VERSION "f34"

NS_ :

BS_:

BU_: C70 VC BMS CHG DASH PBX MCAN OA

BO_ 1286 DS_RC_Outputs: 8 DS
 SG_ DS_Steer : 0|16@1+ (1,0) [0|0] "" Vector__XXX
 SG_ DS_Throttle : 16|16@1+ (1,0) [0|0] "" Vector__XXX

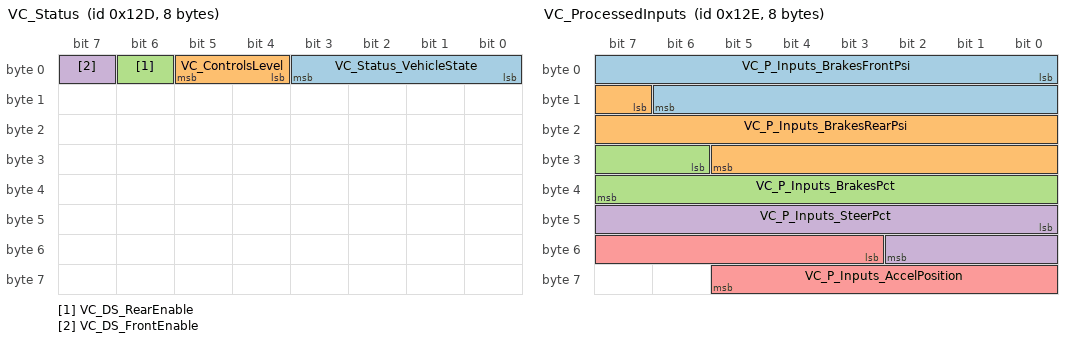
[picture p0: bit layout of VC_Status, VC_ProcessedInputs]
BO_ 301 VC_Status: 8 VC
 SG_ VC_Status_VehicleState : 0|4@1+ (1,0) [0|15] ""  Vector__XXX
 SG_ VC_ControlsLevel : 4|2@1+ (1,0) [0|0] "" Vector__XXX
 SG_ VC_DS_RearEnable : 6|1@1+ (1,0) [0|0] "" Vector__XXX
 SG_ VC_DS_FrontEnable : 7|1@1+ (1,0) [0|0] "" Vector__XXX

BO_ 302 VC_ProcessedInputs: 8 VC
 SG_ VC_P_Inputs_BrakesFrontPsi : 0|15@1+ (0.1,0) [0|3000] "psi" Vector__XXX
 SG_ VC_P_Inputs_BrakesRearPsi : 15|15@1+ (0.1,0) [0|3000] "psi" Vector__XXX
 SG_ VC_P_Inputs_BrakesPct : 30|10@1+ (0.1,0) [0|100] "%" Vector__XXX
 SG_ VC_P_Inputs_SteerPct : 40|11@1- (0.1,0) [-100|100] "%" Vector__XXX
 SG_ VC_P_Inputs_AccelPosition : 51|11@1- (0.1,0) [-100|100] "%" Vector__XXX

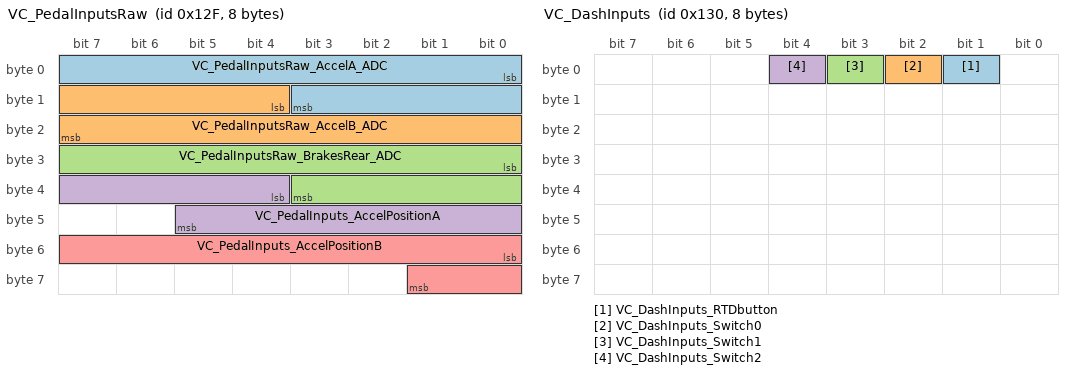
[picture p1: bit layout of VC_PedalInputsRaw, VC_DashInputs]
BO_ 303 VC_PedalInputsRaw: 8 VC
 SG_ VC_PedalInputsRaw_AccelA_ADC : 0|12@1+ (1,0) [0|4095] "" Vector__XXX
 SG_ VC_PedalInputsRaw_AccelB_ADC : 12|12@1+ (1,0) [0|4095] "" Vector__XXX
 SG_ VC_PedalInputsRaw_BrakesRear_ADC : 24|12@1+ (1,0) [0|4095] "" Vector__XXX
 SG_ VC_PedalInputs_AccelPositionA : 36|10@1+ (0.1,0) [0|100] "%" Vector__XXX
 SG_ VC_PedalInputs_AccelPositionB : 48|10@1+ (0.1,0) [0|100] "%" Vector__XXX

BO_ 304 VC_DashInputs: 8 VC
 SG_ VC_DashInputs_RTDbutton : 1|1@1+ (1,0) [0|1] "" Vector__XXX
 SG_ VC_DashInputs_Switch0 : 2|1@1+ (1,0) [0|1] "" Vector__XXX
 SG_ VC_DashInputs_Switch1 : 3|1@1+ (1,0) [0|1] "" Vector__XXX
 SG_ VC_DashInputs_Switch2 : 4|1@1+ (1,0) [0|1] "" Vector__XXX

BO_ 311 VC_FaultVector: 8 VC
 SG_ VC_PBX_SHUTDOWN_CONTROL : 0|1@1+ (1,0) [0|1] ""  Vector__XXX
 SG_ VC_ShutdownStatus_BMS_fault : 1|1@1+ (1,0) [0|1] "" Vector__XXX
 SG_ VC_FaultVector_ACCEL_A_IRRA : 2|1@1+ (1,0) [0|1] "" Vector__XXX
 SG_ VC_FaultVector_ACCEL_B_IRRA : 3|1@1+ (1,0) [0|1] "" Vector__XXX
 SG_ VC_FaultVector_APPS_DISAG : 4|1@1+ (1,0) [0|1] "" Vector__XXX
 SG_ VC_FaultVector_APPS_DOUBLE_PEDAL : 5|1@1+ (1,0) [0|1] "" Vector__XXX
 SG_ VC_FaultVector_FSSDB_LOST : 6|1@1+ (1,0) [0|1] "" Vector__XXX
 SG_ VC_FaultVector_FBPS_IRRA : 7|1@1+ (1,0) [0|1] "" Vector__XXX
 SG_ VC_FaultVector_RBPS_IRRA : 8|1@1+ (1,0) [0|1] "" Vector__XXX
 SG_ VC_FaultVector_STEER_IRRA : 9|1@1+ (1,0) [0|1] ""  Vector__XXX
 SG_ VC_FaultVector_RSSDB_LOST : 10|1@1+ (1,0) [0|1] ""  Vector__XXX
 SG_ VC_FaultVector_RR_ERROR : 11|1@1+ (1,0) [0|1] ""  Vector__XXX
 SG_ VC_FaultVector_RL_ERROR : 12|1@1+ (1,0) [0|1] ""  Vector__XXX
 SG_ VC_FaultVector_FR_ERROR : 13|1@1+ (1,0) [0|1] ""  Vector__XXX
 SG_ VC_FaultVector_FL_ERROR : 14|1@1+ (1,0) [0|1] ""  Vector__XXX
 SG_ VC_FaultVector_PC_TIMEOUT : 15|1@1+ (1,0) [0|1] "" Vector__XXX
 SG_ VC_FaultVector_SOFT_DP : 16|1@1+ (1,0) [0|1] "" Vector__XXX
 SG_ VC_FaultVector_VN_NO_LOCK : 17|1@1+ (1,0) [0|1] "" Vector__XXX
 SG_ VC_FaultVector_VN_IRR : 18|1@1+ (1,0) [0|1] "" Vector__XXX
 SG_ VC_FaultVector_RUNAWAY : 19|1@1+ (1,0) [0|1] "" Vector__XXX
 SG_ VC_FaultVector_CURRENT_IRR : 20|1@1+ (1,0) [0|1] "" Vector__XXX
 SG_ VC_FaultVector_VN_LOST : 21|1@1+ (1,0) [0|1] "" Vector__XXX

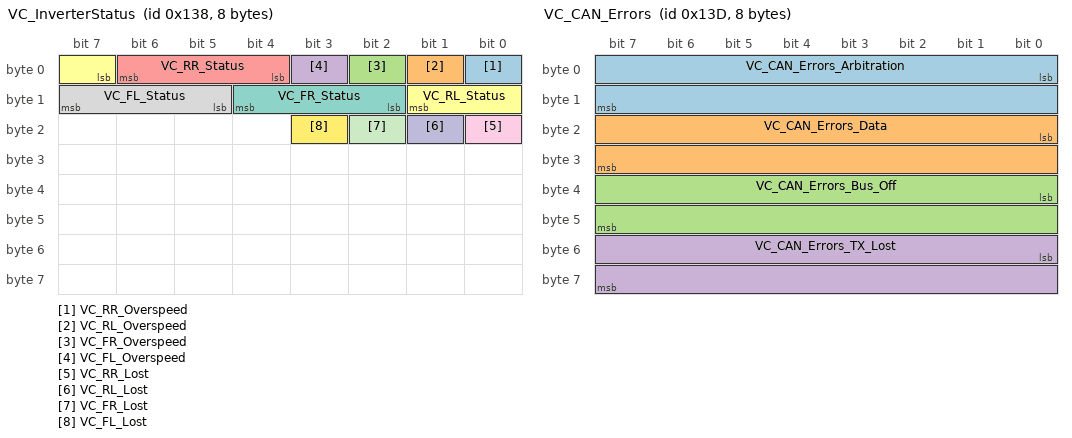
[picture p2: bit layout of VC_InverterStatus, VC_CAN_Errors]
BO_ 312 VC_InverterStatus: 8 VC
 SG_ VC_RR_Overspeed : 0|1@1+ (1,0) [0|1] "" Vector__XXX
 SG_ VC_RL_Overspeed : 1|1@1+ (1,0) [0|1] "" Vector__XXX
 SG_ VC_FR_Overspeed : 2|1@1+ (1,0) [0|1] "" Vector__XXX
 SG_ VC_FL_Overspeed : 3|1@1+ (1,0) [0|1] "" Vector__XXX
 SG_ VC_RR_Status : 4|3@1+ (1,0) [0|7] "" Vector__XXX
 SG_ VC_RL_Status : 7|3@1+ (1,0) [0|7] "" Vector__XXX
 SG_ VC_FR_Status : 10|3@1+ (1,0) [0|7] "" Vector__XXX
 SG_ VC_FL_Status : 13|3@1+ (1,0) [0|7] "" Vector__XXX
 SG_ VC_RR_Lost : 16|1@1+ (1,0) [0|1] "" Vector__XXX
 SG_ VC_RL_Lost : 17|1@1+ (1,0) [0|1] "" Vector__XXX
 SG_ VC_FR_Lost : 18|1@1+ (1,0) [0|1] "" Vector__XXX
 SG_ VC_FL_Lost : 19|1@1+ (1,0) [0|1] "" Vector__XXX

BO_ 315 VC_HardFaultIndicator: 8 VC
 SG_ VC_HardFaultIndicator : 0|4@1+ (1,0) [0|15] ""  DASH

BO_ 316 VC_RTDSRequest: 8 VC
 SG_ VC_RequestRTDS : 0|1@1+ (1,0) [0|1] "" Vector__XXX

BO_ 317 VC_CAN_Errors: 8 VC
 SG_ VC_CAN_Errors_Arbitration : 0|16@1+ (1,0) [0|0] "" Vector__XXX
 SG_ VC_CAN_Errors_Data : 16|16@1+ (1,0) [0|0] "" Vector__XXX
 SG_ VC_CAN_Errors_Bus_Off : 32|16@1+ (1,0) [0|0] "" Vector__XXX
 SG_ VC_CAN_Errors_TX_Lost : 48|16@1+ (1,0) [0|0] "" Vector__XXX

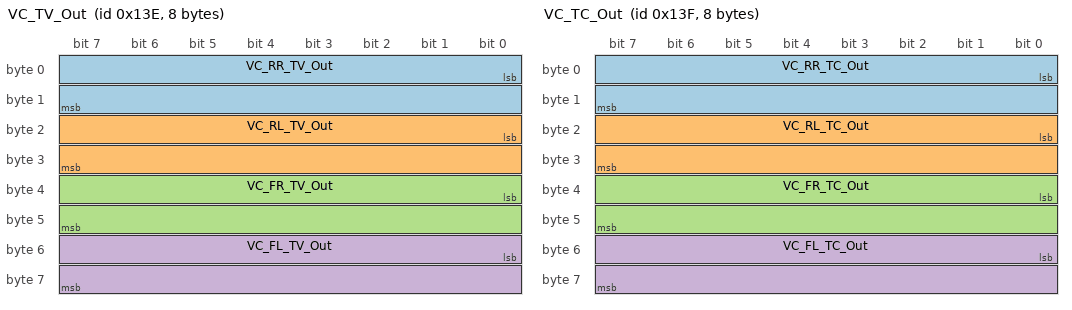
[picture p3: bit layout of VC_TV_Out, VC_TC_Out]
BO_ 318 VC_TV_Out: 8 VC
 SG_ VC_RR_TV_Out: 0|16@1+ (0.1,0) [0|0] "% Mn" Vector__XXX
 SG_ VC_RL_TV_Out: 16|16@1+ (0.1,0) [0|0] "% Mn" Vector__XXX
 SG_ VC_FR_TV_Out: 32|16@1+ (0.1,0) [0|0] "% Mn" Vector__XXX
 SG_ VC_FL_TV_Out: 48|16@1+ (0.1,0) [0|0] "% Mn" Vector__XXX

BO_ 319 VC_TC_Out: 8 VC
 SG_ VC_RR_TC_Out: 0|16@1+ (0.1,0) [0|0] "% Mn" Vector__XXX
 SG_ VC_RL_TC_Out: 16|16@1+ (0.1,0) [0|0] "% Mn" Vector__XXX
 SG_ VC_FR_TC_Out: 32|16@1+ (0.1,0) [0|0] "% Mn" Vector__XXX
 SG_ VC_FL_TC_Out: 48|16@1+ (0.1,0) [0|0] "% Mn" Vector__XXX

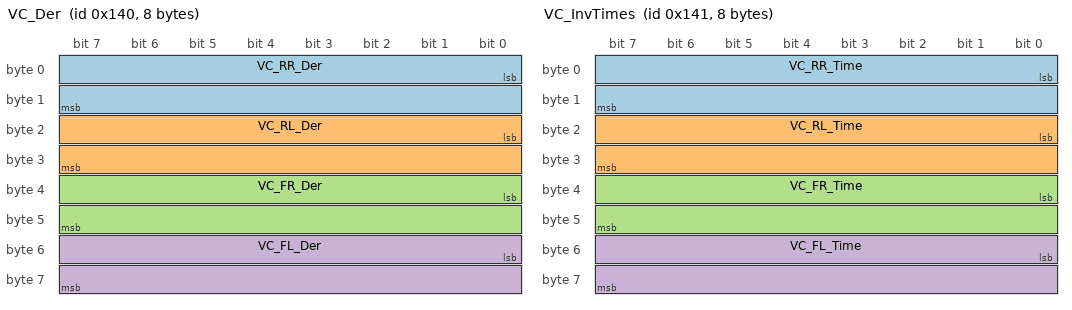
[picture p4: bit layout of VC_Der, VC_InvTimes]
BO_ 320 VC_Der: 8 VC
 SG_ VC_RR_Der: 0|16@1+ (0.1,0) [0|0] "rpm" Vector__XXX
 SG_ VC_RL_Der: 16|16@1+ (0.1,0) [0|0] "rpm" Vector__XXX
 SG_ VC_FR_Der: 32|16@1+ (0.1,0) [0|0] "rpm" Vector__XXX
 SG_ VC_FL_Der: 48|16@1+ (0.1,0) [0|0] "rpm" Vector__XXX

BO_ 321 VC_InvTimes: 8 VC
 SG_ VC_RR_Time : 0|16@1+ (1,0) [0|65535] "" Vector__XXX
 SG_ VC_RL_Time : 16|16@1+ (1,0) [0|65535] "" Vector__XXX
 SG_ VC_FR_Time : 32|16@1+ (1,0) [0|65535] "" Vector__XXX
 SG_ VC_FL_Time : 48|16@1+ (1,0) [0|65535] "" Vector__XXX

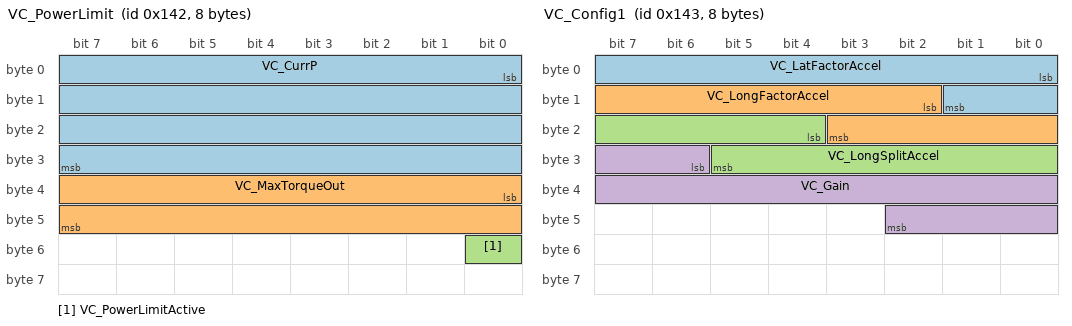
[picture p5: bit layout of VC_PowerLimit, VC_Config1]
BO_ 322 VC_PowerLimit: 8 VC
 SG_ VC_CurrP : 0|32@1+ (0.01,0) [0|0] "W" Vector__XXX
 SG_ VC_MaxTorqueOut : 32|16@1+ (0.1,0) [0|0] "%Mn" Vector__XXX
 SG_ VC_PowerLimitActive : 48|1@1+ (1,0) [0|1] "" Vector__XXX

BO_ 323 VC_Config1: 8 VC
 SG_ VC_LatFactorAccel : 0|10@1+ (0.01,0) [0|0] "" Vector__XXX
 SG_ VC_LongFactorAccel : 10|10@1+ (0.01,0) [0|0] "" Vector__XXX
 SG_ VC_LongSplitAccel : 20|10@1+ (0.01,0) [0|0] "" Vector__XXX
 SG_ VC_Gain : 30|13@1+ (0.01,0) [0|0] "" Vector__XXX

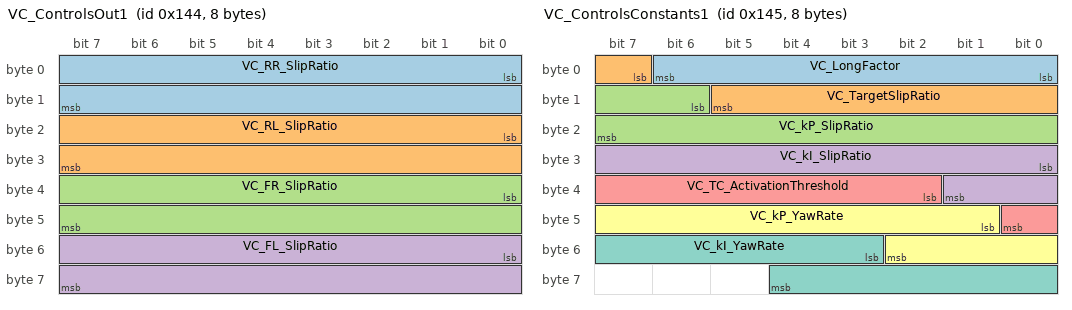
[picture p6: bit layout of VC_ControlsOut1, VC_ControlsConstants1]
BO_ 324 VC_ControlsOut1: 8 VC
 SG_ VC_RR_SlipRatio : 0|16@1+ (0.001,0) [0|0] "" Vector__XXX
 SG_ VC_RL_SlipRatio : 16|16@1+ (0.001,0) [0|0] "" Vector__XXX
 SG_ VC_FR_SlipRatio : 32|16@1+ (0.001,0) [0|0] "" Vector__XXX
 SG_ VC_FL_SlipRatio : 48|16@1+ (0.001,0) [0|0] "" Vector__XXX

BO_ 325 VC_ControlsConstants1 : 8 VC
 SG_ VC_LongFactor : 0|7@1+ (0.01,0) [0|0] "" Vector__XXX
 SG_ VC_TargetSlipRatio : 7|7@1+ (0.01,0) [0|0] "" Vector__XXX
 SG_ VC_kP_SlipRatio : 14|10@1+ (0.01,0) [0|0] "" Vector__XXX
 SG_ VC_kI_SlipRatio : 24|10@1+ (0.01,0) [0|0] "" Vector__XXX
 SG_ VC_TC_ActivationThreshold : 34|7@1+ (0.01,0) [0|0] "" Vector__XXX
 SG_ VC_kP_YawRate : 41|10@1+ (0.01,0) [0|0] "" Vector__XXX
 SG_ VC_kI_YawRate : 51|10@1+ (0.01,0) [0|0] "" Vector__XXX

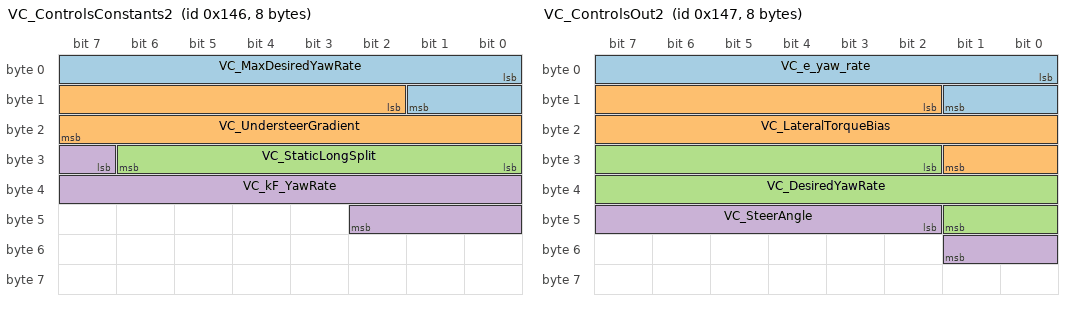
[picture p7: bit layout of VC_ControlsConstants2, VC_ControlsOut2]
BO_ 326 VC_ControlsConstants2 : 8 VC
 SG_ VC_MaxDesiredYawRate : 0|10@1+ (0.01,0) [0|0] "" Vector__XXX
 SG_ VC_UndersteerGradient : 10|14@1+ (0.00001,0) [0|0] "" Vector__XXX
 SG_ VC_StaticLongSplit : 24|7@1+ (0.01,0) [0|0] "" Vector__XXX
 SG_ VC_kF_YawRate : 31|12@1+ (0.01, 0) [0|0] "" Vector__XXX

BO_ 327 VC_ControlsOut2: 8 VC
 SG_ VC_e_yaw_rate : 0|10@1- (0.01,0) [0|0] "rad/s" Vector__XXX
 SG_ VC_LateralTorqueBias : 10|16@1- (0.01,0) [0|0] "Nm" Vector__XXX
 SG_ VC_DesiredYawRate : 26|16@1- (0.001,0) [0|0] "rad/s" Vector__XXX
 SG_ VC_SteerAngle : 42|8@1- (1,0) [0|0] "deg" Vector__XXX

BO_ 328 VC_ControlsDebug: 8 VC
 SG_ VC_debug1 : 0|32@1+ (1,0) [0|0] "" Vector__XXX
 SG_ VC_debug2 : 32|32@1+ (1,0) [0|0] "" Vector__XXX

BO_ 329 VC_ControlsOut3: 8 VC
 SG_ VC_YawRateProportional : 0|32@1+ (1,0) [0|0] "Nm" Vector__XXX
 SG_ VC_YawRateIntegral : 32|32@1+ (1,0) [0|0] "Nm" Vector__XXX

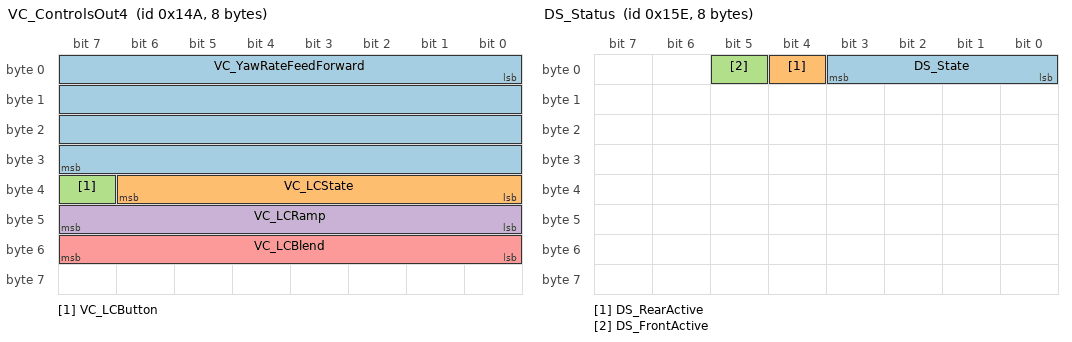
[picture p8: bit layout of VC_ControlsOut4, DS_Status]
BO_ 330 VC_ControlsOut4: 8 VC
 SG_ VC_YawRateFeedForward : 0|32@1+ (1,0) [0|0] "Nm" Vector__XXX
 SG_ VC_LCState: 32|7@1+ (1,0) [0|0] "" Vector__XXX
 SG_ VC_LCButton: 39|1@1+ (1,0) [0|0] "" Vector__XXX
 SG_ VC_LCRamp: 40|8@1+ (1,0) [0|0] "" Vector__XXX
 SG_ VC_LCBlend: 48|8@1+ (1,0) [0|0] "" Vector__XXX

BO_ 331 VC_CodegenOutRear: 8 VC
 SG_ VC_CodegenRR : 0|32@1- (1,0) [0|0] "Nm" Vector__XXX
 SG_ VC_CodegenRL : 32|32@1- (1,0) [0|0] "Nm" Vector__XXX

BO_ 332 VC_CodegenOutFront: 8 VC
 SG_ VC_CodegenFR : 0|32@1- (1,0) [0|0] "Nm" Vector__XXX
 SG_ VC_CodegenFL : 32|32@1- (1,0) [0|0] "Nm" Vector__XXX

BO_ 333 VC_VectorNAV_Status: 8 VC
 SG_ VC_VectorNAV_Packets : 0|16@1+ (1,0) [0|0] "" Vector__XXX
 SG_ VC_VectorNAV_Errors : 16|16@1+ (1,0) [0|0] "" Vector__XXX

BO_ 350 DS_Status: 8 LOG
 SG_ DS_State : 0|4@1+ (1,0) [0|0] "" Vector__XXX
 SG_ DS_RearActive : 4|1@1+ (1,0) [0|0] "" Vector__XXX
 SG_ DS_FrontActive : 5|1@1+ (1,0) [0|0] "" Vector__XXX

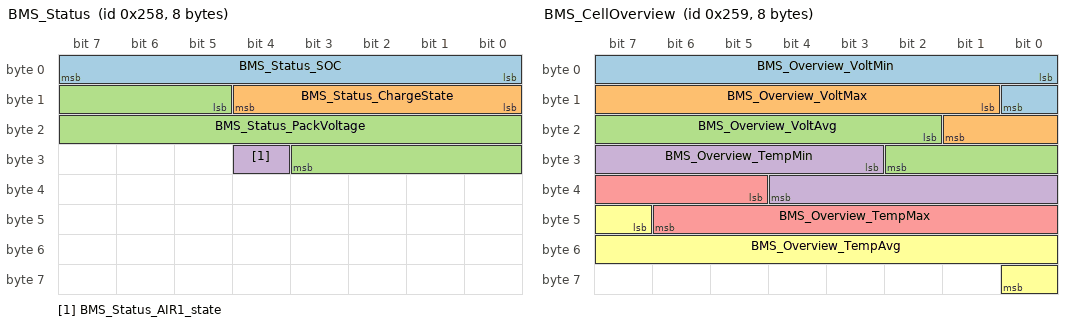
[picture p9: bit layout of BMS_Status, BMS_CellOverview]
BO_ 600 BMS_Status: 8 BMS
 SG_ BMS_Status_SOC : 0|8@1+ (1,0) [0|100] "%"  Vector__XXX
 SG_ BMS_Status_ChargeState : 8|5@1+ (1,0) [0|5] "" Vector__XXX
 SG_ BMS_Status_PackVoltage : 13|15@1+ (0.1,0) [0|400] "V"  Vector__XXX
 SG_ BMS_Status_AIR1_state : 28|1@1+ (1,0) [0|1] "" Vector__XXX

BO_ 601 BMS_CellOverview: 8 BMS
 SG_ BMS_Overview_VoltMin : 0|9@1+ (0.01,0) [0|5.12] "V" Vector__XXX
 SG_ BMS_Overview_VoltMax : 9|9@1+ (0.01,0) [0|5.12] "V" Vector__XXX
 SG_ BMS_Overview_VoltAvg : 18|9@1+ (0.01,0) [0|5.12] "V" Vector__XXX
 SG_ BMS_Overview_TempMin : 27|10@1+ (0.1,0) [0|102.3] "C" Vector__XXX
 SG_ BMS_Overview_TempMax : 37|10@1+ (0.1,0) [0|102.3] "C" Vector__XXX
 SG_ BMS_Overview_TempAvg : 47|10@1+ (0.1,0) [0|102.3] "C" Vector__XXX

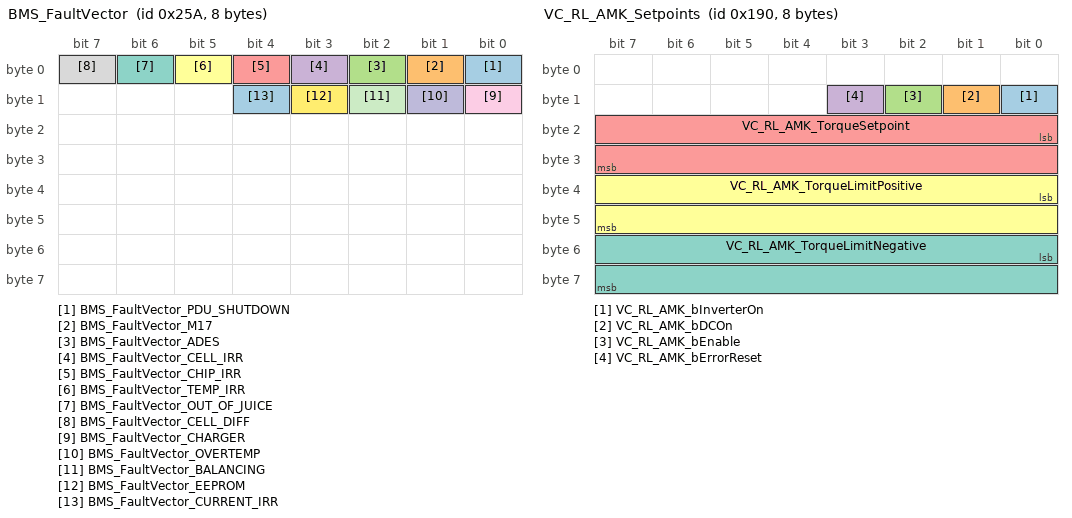
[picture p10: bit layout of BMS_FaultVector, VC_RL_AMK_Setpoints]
BO_ 602 BMS_FaultVector: 8 BMS
 SG_ BMS_FaultVector_PDU_SHUTDOWN : 0|1@1+ (1,0) [0|1] ""  Vector__XXX
 SG_ BMS_FaultVector_M17 : 1|1@1+ (1,0) [0|1] ""  Vector__XXX
 SG_ BMS_FaultVector_ADES : 2|1@1+ (1,0) [0|1] ""  Vector__XXX
 SG_ BMS_FaultVector_CELL_IRR : 3|1@1+ (1,0) [0|1] ""  Vector__XXX
 SG_ BMS_FaultVector_CHIP_IRR : 4|1@1+ (1,0) [0|1] ""  Vector__XXX
 SG_ BMS_FaultVector_TEMP_IRR : 5|1@1+ (1,0) [0|1] ""  Vector__XXX
 SG_ BMS_FaultVector_OUT_OF_JUICE : 6|1@1+ (1,0) [0|1] ""  Vector__XXX
 SG_ BMS_FaultVector_CELL_DIFF : 7|1@1+ (1,0) [0|1] ""  Vector__XXX
 SG_ BMS_FaultVector_CHARGER : 8|1@1+ (1,0) [0|1] ""  Vector__XXX
 SG_ BMS_FaultVector_OVERTEMP : 9|1@1+ (1,0) [0|1] ""  Vector__XXX
 SG_ BMS_FaultVector_BALANCING : 10|1@1+ (1,0) [0|1] ""  Vector__XXX
 SG_ BMS_FaultVector_EEPROM : 11|1@1+ (1,0) [0|1] ""  Vector__XXX
 SG_ BMS_FaultVector_CURRENT_IRR : 12|1@1+ (1,0) [0|1] ""  Vector__XXX

BO_ 603 BMS_ErrorList: 8 BMS
 SG_ BMS_Error_TX_NOT_RECEIVED :              0|1@1+ (1,0) [0|1] ""  Vector__XXX
 SG_ BMS_Error_LOOPBACK_MISMATCH :            1|1@1+ (1,0) [0|1] ""  Vector__XXX
 SG_ BMS_Error_NUM_CHIPS_MISMATCH :           2|1@1+ (1,0) [0|1] ""  Vector__XXX
 SG_ BMS_Error_ERR_LSSM_BYTE :                3|1@1+ (1,0) [0|1] ""  Vector__XXX
 SG_ BMS_Error_ERR_LSSM_COMM_ERR :            4|1@1+ (1,0) [0|1] ""  Vector__XXX
 SG_ BMS_Error_ERR_ALERT_RX :                 5|1@1+ (1,0) [0|1] ""  Vector__XXX
 SG_ BMS_Error_ERR_ALERT_RX_OVERFLOW :        6|1@1+ (1,0) [0|1] ""  Vector__XXX
 SG_ BMS_Error_ERR_LDQ_READ :                 7|1@1+ (1,0) [0|1] ""  Vector__XXX
 SG_ BMS_Error_ERR_LDQ_FULL :                 8|1@1+ (1,0) [0|1] ""  Vector__XXX
 SG_ BMS_Error_ERR_RX_TIMEOUT :               9|1@1+ (1,0) [0|1] ""  Vector__XXX
 SG_ BMS_Error_ERR_NO_RX :                   10|1@1+ (1,0) [0|1] ""  Vector__XXX
 SG_ BMS_Error_ERR_ADES_SCAN_TIMEOUT :       11|1@1+ (1,0) [0|1] ""  Vector__XXX
 SG_ BMS_Error_ERR_RX_DATA :                 12|1@1+ (1,0) [0|1] ""  Vector__XXX
 SG_ BMS_Error_ERR_TX_NOT_WRITTEN :          13|1@1+ (1,0) [0|1] ""  Vector__XXX
 SG_ BMS_Error_ERR_NO_WAKE :                 14|1@1+ (1,0) [0|1] ""  Vector__XXX
 SG_ BMS_Error_ERR_CAL_TIMEOUT :             15|1@1+ (1,0) [0|1] ""  Vector__XXX
 SG_ BMS_Error_ERR_RX_OVRFLW :               16|1@1+ (1,0) [0|1] ""  Vector__XXX
 SG_ BMS_Error_ERR_BALANCING_NO_INIT :       20|1@1+ (1,0) [0|1] ""  Vector__XXX
 SG_ BMS_Error_ERR_BALANCING_FAULT :         21|1@1+ (1,0) [0|1] ""  Vector__XXX
 SG_ BMS_Error_ERR_CHARGING_DISCONNECTED :   22|1@1+ (1,0) [0|1] ""  Vector__XXX
 SG_ BMS_Error_ERR_EEPROM_WIP :              28|1@1+ (1,0) [0|1] ""  Vector__XXX
 SG_ BMS_Error_ERR_EEPROM_WEL :              29|1@1+ (1,0) [0|1] ""  Vector__XXX

BO_ 604 BMS_Current: 8 BMS
 SG_ BMS_InstCurrentFilt : 0|32@1- (0.001,0) [0|0] "A" Vector__XXX
 SG_ BMS_Current : 32|32@1- (0.001,0) [0|0] "A" Vector__XXX

BO_ 504 SSDB_front: 3 SSDB
 SG_ SSDB_brake_pressure_front_raw : 0|12@1+ (1,0) [0|4095] "" Vector__XXX
 SG_ SSDB_steering_angle_raw : 12|12@1+ (1,0) [0|4095] "" Vector__XXX

BO_ 400 VC_RL_AMK_Setpoints: 8 VC
 SG_ VC_RL_AMK_bInverterOn : 8|1@1+ (1,0) [0|1] "" Vector__XXX
 SG_ VC_RL_AMK_bDCOn : 9|1@1+ (1,0) [0|1] "" Vector__XXX
 SG_ VC_RL_AMK_bEnable : 10|1@1+ (1,0) [0|1] "" Vector__XXX
 SG_ VC_RL_AMK_bErrorReset : 11|1@1+ (1,0) [0|1] "" Vector__XXX
 SG_ VC_RL_AMK_TorqueSetpoint : 16|16@1- (0.1, 0) [-1000|1000] "% Mn" Vector__XXX
 SG_ VC_RL_AMK_TorqueLimitPositive : 32|16@1- (0.1, 0) [-3000|3000] "% Mn" Vector__XXX
 SG_ VC_RL_AMK_TorqueLimitNegative : 48|16@1- (0.1, 0) [-3000|3000] "% Mn" Vector__XXX

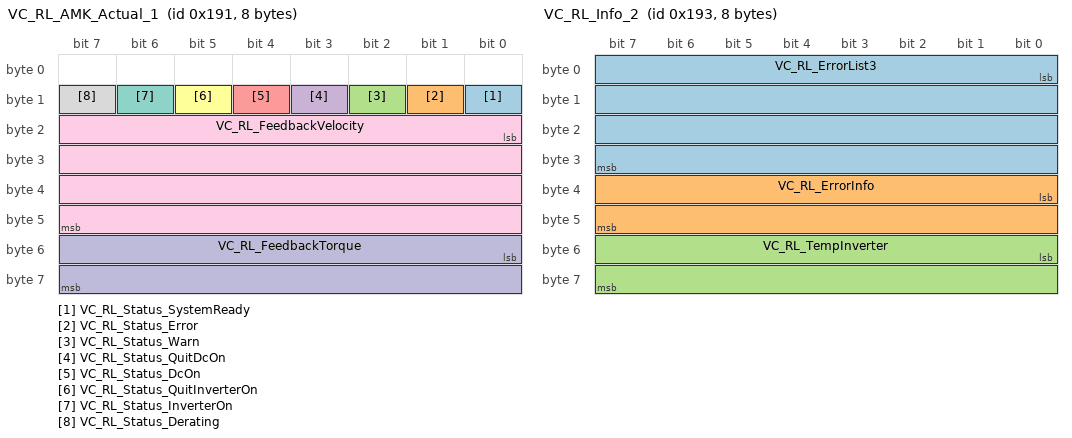
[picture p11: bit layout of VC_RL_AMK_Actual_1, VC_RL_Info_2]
BO_ 401 VC_RL_AMK_Actual_1: 8 VC
 SG_ VC_RL_Status_SystemReady : 8|1@1+ (1,0) [0|1] "" Vector__XXX
 SG_ VC_RL_Status_Error : 9|1@1+ (1,0) [0|1] "" Vector__XXX
 SG_ VC_RL_Status_Warn : 10|1@1+ (1,0) [0|1] "" Vector__XXX
 SG_ VC_RL_Status_QuitDcOn : 11|1@1+ (1,0) [0|1] "" Vector__XXX
 SG_ VC_RL_Status_DcOn : 12|1@1+ (1,0) [0|1] "" Vector__XXX
 SG_ VC_RL_Status_QuitInverterOn : 13|1@1+ (1,0) [0|1] "" Vector__XXX
 SG_ VC_RL_Status_InverterOn : 14|1@1+ (1,0) [0|1] "" Vector__XXX
 SG_ VC_RL_Status_Derating : 15|1@1+ (1,0) [0|1] "" Vector__XXX
 SG_ VC_RL_FeedbackVelocity : 16|32@1- (0.0001,0) [-100000.0|100000.0] "rpm" Vector__XXX
 SG_ VC_RL_FeedbackTorque : 48|16@1- (0.1,0) [-3000.0|3000.0] "% Mn" Vector__XXX

BO_ 402 VC_RL_Info_1: 8 VC
 SG_ VC_RL_ErrorList1 : 0|32@1+ (1,0) [0|0] "" Vector__XXX
 SG_ VC_RL_ErrorList2 : 32|32@1+ (1,0) [0|0] "" Vector__XXX

BO_ 403 VC_RL_Info_2: 8 VC
 SG_ VC_RL_ErrorList3 : 0|32@1+ (1,0) [0|0] "" Vector__XXX
 SG_ VC_RL_ErrorInfo : 32|16@1+ (1,0) [0|65535] "" Vector__XXX
 SG_ VC_RL_TempInverter : 48|16@1- (0.1,0) [-3276.8|3276.7] "degC" Vector__XXX

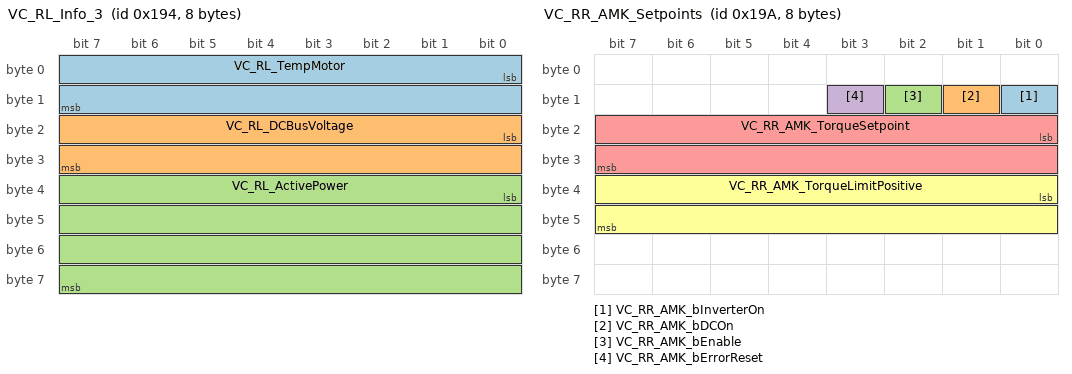
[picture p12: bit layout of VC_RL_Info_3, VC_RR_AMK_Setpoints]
BO_ 404 VC_RL_Info_3: 8 VC
 SG_ VC_RL_TempMotor : 0|16@1- (0.1,0) [-3276.8|3276.7] "degC" Vector__XXX
 SG_ VC_RL_DCBusVoltage : 16|16@1+ (1,0) [0|4096] "V" Vector__XXX
 SG_ VC_RL_ActivePower : 32|32@1- (1,0) [-32768|32767] "W" Vector__XXX

BO_ 405 VC_RL_AMK_RITSet4: 4 VC
 SG_ RL_ActualPowerBipolar : 0|32@1- (1,0) [0|0] "W" Vector__XXX

BO_ 406 VC_RL_AMK_RIT_Set5: 4 VC
 SG_ RL_MagnetizingCurrent: 0|32@1- (0.001,0) [0|0] "A" Vector__XXX

BO_ 407 VC_RL_AMK_RIT_Set6: 4 VC
 SG_ RL_TorqueCurrentFeedback: 0|32@1- (0.001,0) [0|0] "A" Vector__XXX

BO_ 410 VC_RR_AMK_Setpoints: 8 VC
 SG_ VC_RR_AMK_bInverterOn : 8|1@1+ (1,0) [0|1] "" Vector__XXX
 SG_ VC_RR_AMK_bDCOn : 9|1@1+ (1,0) [0|1] "" Vector__XXX
 SG_ VC_RR_AMK_bEnable : 10|1@1+ (1,0) [0|1] "" Vector__XXX
 SG_ VC_RR_AMK_bErrorReset : 11|1@1+ (1,0) [0|1] "" Vector__XXX
 SG_ VC_RR_AMK_TorqueSetpoint : 16|16@1- (0.1, 0) [-1000|1000] "% Mn" Vector__XXX
 SG_ VC_RR_AMK_TorqueLimitPositive : 32|16@1- (0.1, 0) [-3000|3000] "% Mn" Vector__XXX

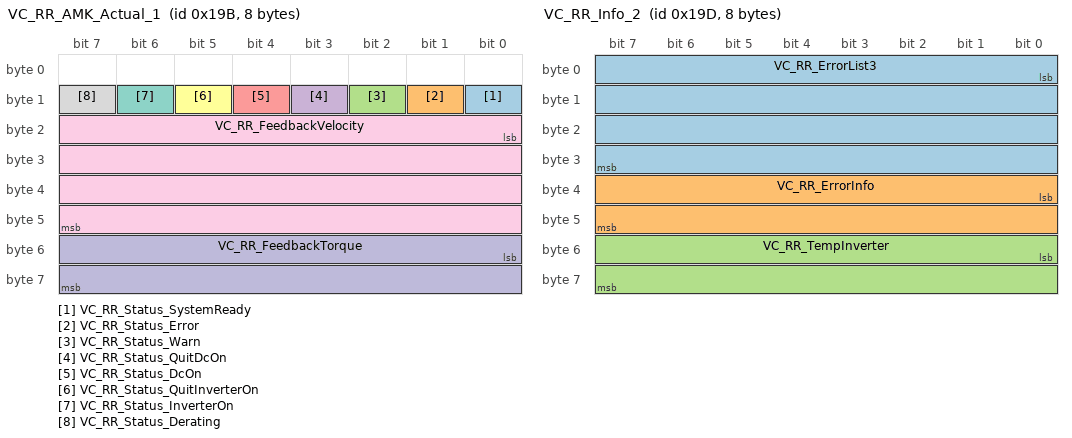
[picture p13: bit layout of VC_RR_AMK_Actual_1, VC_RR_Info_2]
BO_ 411 VC_RR_AMK_Actual_1: 8 VC
 SG_ VC_RR_Status_SystemReady : 8|1@1+ (1,0) [0|1] "" Vector__XXX
 SG_ VC_RR_Status_Error : 9|1@1+ (1,0) [0|1] "" Vector__XXX
 SG_ VC_RR_Status_Warn : 10|1@1+ (1,0) [0|1] "" Vector__XXX
 SG_ VC_RR_Status_QuitDcOn : 11|1@1+ (1,0) [0|1] "" Vector__XXX
 SG_ VC_RR_Status_DcOn : 12|1@1+ (1,0) [0|1] "" Vector__XXX
 SG_ VC_RR_Status_QuitInverterOn : 13|1@1+ (1,0) [0|1] "" Vector__XXX
 SG_ VC_RR_Status_InverterOn : 14|1@1+ (1,0) [0|1] "" Vector__XXX
 SG_ VC_RR_Status_Derating : 15|1@1+ (1,0) [0|1] "" Vector__XXX
 SG_ VC_RR_FeedbackVelocity : 16|32@1- (0.0001,0) [-100000.0|100000.0] "rpm" Vector__XXX
 SG_ VC_RR_FeedbackTorque : 48|16@1- (0.1,0) [-3000.0|3000.0] "% Mn" Vector__XXX

BO_ 412 VC_RR_Info_1: 8 VC
 SG_ VC_RR_ErrorList1 : 0|32@1+ (1,0) [0|0] "" Vector__XXX
 SG_ VC_RR_ErrorList2 : 32|32@1+ (1,0) [0|0] "" Vector__XXX

BO_ 413 VC_RR_Info_2: 8 VC
 SG_ VC_RR_ErrorList3 : 0|32@1+ (1,0) [0|0] "" Vector__XXX
 SG_ VC_RR_ErrorInfo : 32|16@1+ (1,0) [0|65535] "" Vector__XXX
 SG_ VC_RR_TempInverter : 48|16@1- (0.1,0) [-3276.8|3276.7] "degC" Vector__XXX

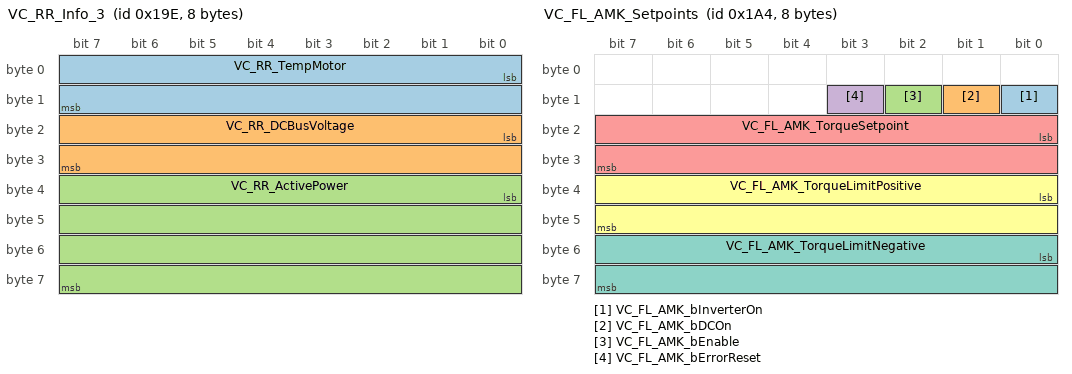
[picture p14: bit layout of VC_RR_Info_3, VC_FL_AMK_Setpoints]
BO_ 414 VC_RR_Info_3: 8 VC
 SG_ VC_RR_TempMotor : 0|16@1- (0.1,0) [-3276.8|3276.7] "degC" Vector__XXX
 SG_ VC_RR_DCBusVoltage : 16|16@1+ (1,0) [0|4096] "V" Vector__XXX
 SG_ VC_RR_ActivePower : 32|32@1- (1,0) [-32768|32767] "W" Vector__XXX

BO_ 415 VC_RR_AMK_RITSet4: 4 VC
 SG_ RR_ActualPowerBipolar : 0|32@1- (1,0) [0|0] "W" Vector__XXX

BO_ 416 VC_RR_AMK_RIT_Set5: 4 VC
 SG_ RR_MagnetizingCurrent: 0|32@1- (0.001,0) [0|0] "A" Vector__XXX

BO_ 417 VC_RR_AMK_RIT_Set6: 4 VC
 SG_ RR_TorqueCurrentFeedback: 0|32@1- (0.001,0) [0|0] "A" Vector__XXX

BO_ 420 VC_FL_AMK_Setpoints: 8 VC
 SG_ VC_FL_AMK_bInverterOn : 8|1@1+ (1,0) [0|1] "" Vector__XXX
 SG_ VC_FL_AMK_bDCOn : 9|1@1+ (1,0) [0|1] "" Vector__XXX
 SG_ VC_FL_AMK_bEnable : 10|1@1+ (1,0) [0|1] "" Vector__XXX
 SG_ VC_FL_AMK_bErrorReset : 11|1@1+ (1,0) [0|1] "" Vector__XXX
 SG_ VC_FL_AMK_TorqueSetpoint : 16|16@1- (0.1, 0) [-1000|1000] "% Mn" Vector__XXX
 SG_ VC_FL_AMK_TorqueLimitPositive : 32|16@1- (0.1, 0) [-3000|3000] "% Mn" Vector__XXX
 SG_ VC_FL_AMK_TorqueLimitNegative : 48|16@1- (0.1, 0) [-3000|3000] "% Mn" Vector__XXX

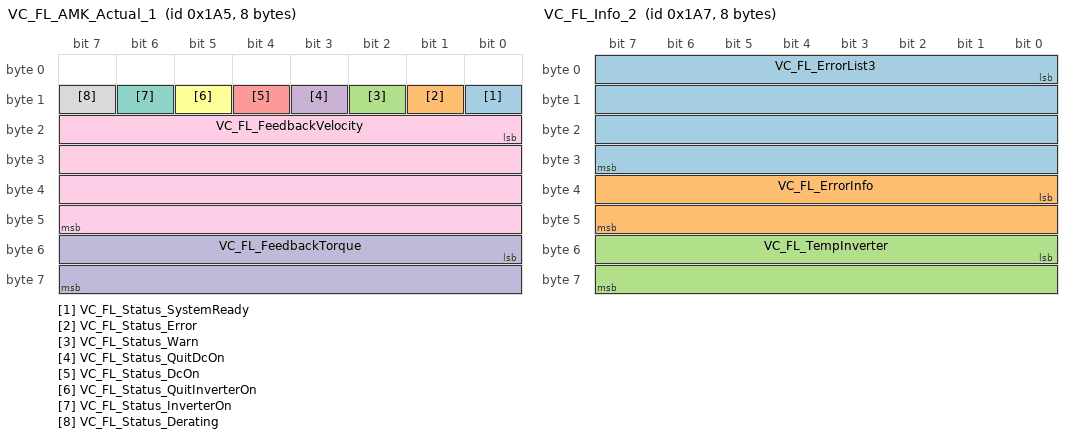
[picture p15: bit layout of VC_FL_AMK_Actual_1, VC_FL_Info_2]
BO_ 421 VC_FL_AMK_Actual_1: 8 VC
 SG_ VC_FL_Status_SystemReady : 8|1@1+ (1,0) [0|1] "" Vector__XXX
 SG_ VC_FL_Status_Error : 9|1@1+ (1,0) [0|1] "" Vector__XXX
 SG_ VC_FL_Status_Warn : 10|1@1+ (1,0) [0|1] "" Vector__XXX
 SG_ VC_FL_Status_QuitDcOn : 11|1@1+ (1,0) [0|1] "" Vector__XXX
 SG_ VC_FL_Status_DcOn : 12|1@1+ (1,0) [0|1] "" Vector__XXX
 SG_ VC_FL_Status_QuitInverterOn : 13|1@1+ (1,0) [0|1] "" Vector__XXX
 SG_ VC_FL_Status_InverterOn : 14|1@1+ (1,0) [0|1] "" Vector__XXX
 SG_ VC_FL_Status_Derating : 15|1@1+ (1,0) [0|1] "" Vector__XXX
 SG_ VC_FL_FeedbackVelocity : 16|32@1- (0.0001,0) [-100000.0|100000.0] "rpm" Vector__XXX
 SG_ VC_FL_FeedbackTorque : 48|16@1- (0.1,0) [-3000.0|3000.0] "% Mn" Vector__XXX

BO_ 422 VC_Fl_Info_1: 8 VC
 SG_ VC_FL_ErrorList1 : 0|32@1+ (1,0) [0|0] "" Vector__XXX
 SG_ VC_FL_ErrorList2 : 32|32@1+ (1,0) [0|0] "" Vector__XXX

BO_ 423 VC_FL_Info_2: 8 VC
 SG_ VC_FL_ErrorList3 : 0|32@1+ (1,0) [0|0] "" Vector__XXX
 SG_ VC_FL_ErrorInfo : 32|16@1+ (1,0) [0|65535] "" Vector__XXX
 SG_ VC_FL_TempInverter : 48|16@1- (0.1,0) [-3276.8|3276.7] "degC" Vector__XXX

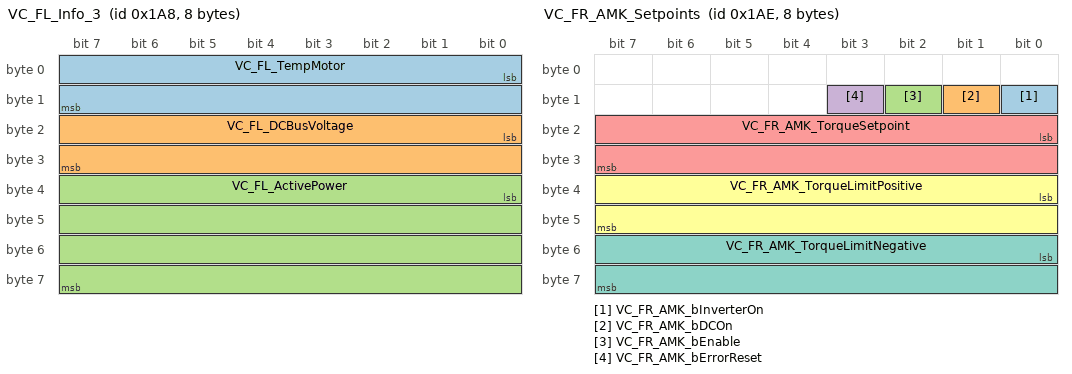
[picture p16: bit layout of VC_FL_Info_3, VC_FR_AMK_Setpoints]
BO_ 424 VC_FL_Info_3: 8 VC
 SG_ VC_FL_TempMotor : 0|16@1- (0.1,0) [-3276.8|3276.7] "degC" Vector__XXX
 SG_ VC_FL_DCBusVoltage : 16|16@1+ (1,0) [0|4096] "V" Vector__XXX
 SG_ VC_FL_ActivePower : 32|32@1- (1,0) [-32768|32767] "W" Vector__XXX

BO_ 425 VC_FL_AMK_RITSet4: 4 VC
 SG_ FL_ActualPowerBipolar : 0|32@1- (1,0) [0|0] "W" Vector__XXX

BO_ 426 VC_FL_AMK_RIT_Set5: 4 VC
 SG_ FL_MagnetizingCurrent: 0|32@1- (0.001,0) [0|0] "A" Vector__XXX

BO_ 427 VC_FL_AMK_RIT_Set6: 4 VC
 SG_ FL_TorqueCurrentFeedback: 0|32@1- (0.001,0) [0|0] "A" Vector__XXX

BO_ 430 VC_FR_AMK_Setpoints: 8 VC
 SG_ VC_FR_AMK_bInverterOn : 8|1@1+ (1,0) [0|1] "" Vector__XXX
 SG_ VC_FR_AMK_bDCOn : 9|1@1+ (1,0) [0|1] "" Vector__XXX
 SG_ VC_FR_AMK_bEnable : 10|1@1+ (1,0) [0|1] "" Vector__XXX
 SG_ VC_FR_AMK_bErrorReset : 11|1@1+ (1,0) [0|1] "" Vector__XXX
 SG_ VC_FR_AMK_TorqueSetpoint : 16|16@1- (0.1, 0) [-1000|1000] "% Mn" Vector__XXX
 SG_ VC_FR_AMK_TorqueLimitPositive : 32|16@1- (0.1, 0) [-3000|3000] "% Mn" Vector__XXX
 SG_ VC_FR_AMK_TorqueLimitNegative : 48|16@1- (0.1, 0) [-3000|3000] "% Mn" Vector__XXX

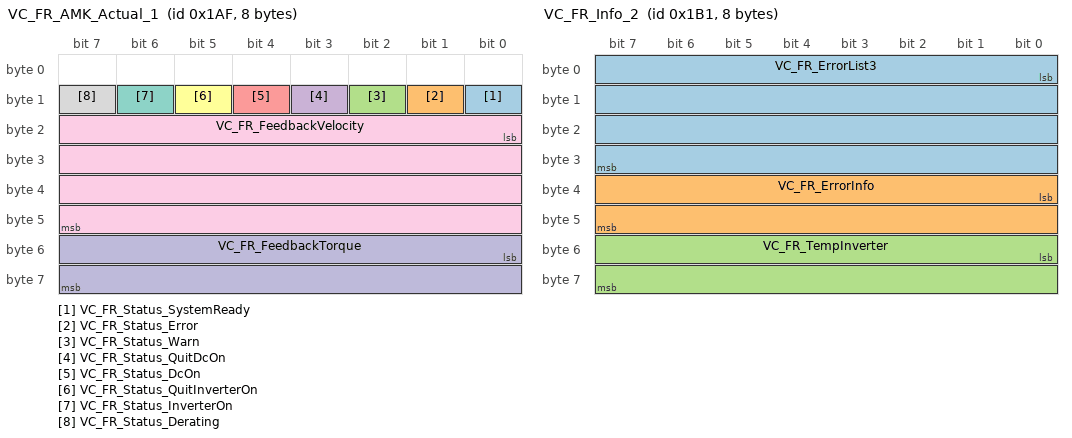
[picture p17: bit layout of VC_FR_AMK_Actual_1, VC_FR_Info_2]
BO_ 431 VC_FR_AMK_Actual_1: 8 VC
 SG_ VC_FR_Status_SystemReady : 8|1@1+ (1,0) [0|1] "" Vector__XXX
 SG_ VC_FR_Status_Error : 9|1@1+ (1,0) [0|1] "" Vector__XXX
 SG_ VC_FR_Status_Warn : 10|1@1+ (1,0) [0|1] "" Vector__XXX
 SG_ VC_FR_Status_QuitDcOn : 11|1@1+ (1,0) [0|1] "" Vector__XXX
 SG_ VC_FR_Status_DcOn : 12|1@1+ (1,0) [0|1] "" Vector__XXX
 SG_ VC_FR_Status_QuitInverterOn : 13|1@1+ (1,0) [0|1] "" Vector__XXX
 SG_ VC_FR_Status_InverterOn : 14|1@1+ (1,0) [0|1] "" Vector__XXX
 SG_ VC_FR_Status_Derating : 15|1@1+ (1,0) [0|1] "" Vector__XXX
 SG_ VC_FR_FeedbackVelocity : 16|32@1- (0.0001,0) [-100000.0|100000.0] "rpm" Vector__XXX
 SG_ VC_FR_FeedbackTorque : 48|16@1- (0.1,0) [-3000.0|3000.0] "% Mn" Vector__XXX

BO_ 432 VC_FR_Info_1: 8 VC
 SG_ VC_FR_ErrorList1 : 0|32@1+ (1,0) [0|0] "" Vector__XXX
 SG_ VC_FR_ErrorList2 : 32|32@1+ (1,0) [0|0] "" Vector__XXX

BO_ 433 VC_FR_Info_2: 8 VC
 SG_ VC_FR_ErrorList3 : 0|32@1+ (1,0) [0|0] "" Vector__XXX
 SG_ VC_FR_ErrorInfo : 32|16@1+ (1,0) [0|65535] "" Vector__XXX
 SG_ VC_FR_TempInverter : 48|16@1- (0.1,0) [-3276.8|3276.7] "degC" Vector__XXX

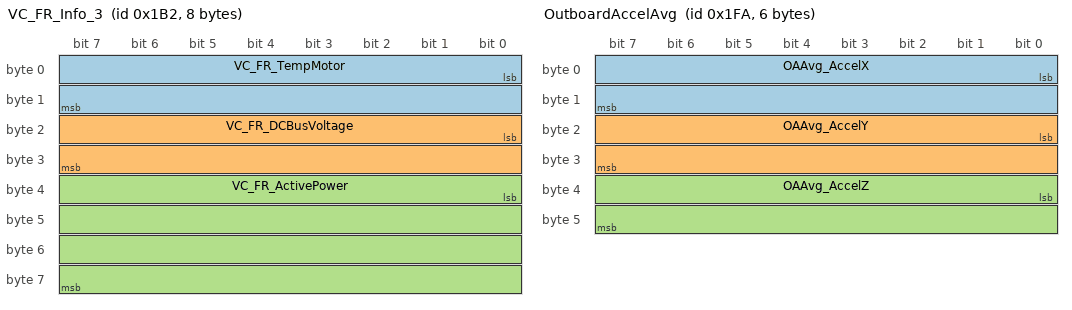
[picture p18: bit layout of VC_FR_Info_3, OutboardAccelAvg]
BO_ 434 VC_FR_Info_3: 8 VC
 SG_ VC_FR_TempMotor : 0|16@1- (0.1,0) [-3276.8|3276.7] "degC" Vector__XXX
 SG_ VC_FR_DCBusVoltage : 16|16@1+ (1,0) [0|4096] "V" Vector__XXX
 SG_ VC_FR_ActivePower : 32|32@1- (1,0) [-32768|32767] "W" Vector__XXX

BO_ 435 VC_FR_AMK_RITSet4: 4 VC
 SG_ FR_ActualPowerBipolar : 0|32@1- (1,0) [0|0] "W" Vector__XXX

BO_ 436 VC_FR_AMK_RIT_Set5: 4 VC
 SG_ FR_MagnetizingCurrent: 0|32@1- (0.001,0) [0|0] "A" Vector__XXX

BO_ 437 VC_FR_AMK_RIT_Set6: 4 VC
 SG_ FR_TorqueCurrentFeedback: 0|32@1- (0.001,0) [0|0] "A" Vector__XXX

BO_ 520 SSDB_suspension_front: 3 SSDB
 SG_ SSDB_suspension_FL : 0|12@1+ (1,0) [0|4095] "" Vector__XXX
 SG_ SSDB_suspension_FR : 12|12@1+ (1,0) [0|4095] "" Vector__XXX

BO_ 521 SSDB_suspension_rear: 3 SSDB
 SG_ SSDB_suspension_RL : 0|12@1+ (1,0) [0|4095] "" Vector__XXX
 SG_ SSDB_suspension_RR : 12|12@1+ (1,0) [0|4095] "" Vector__XXX

BO_ 506 OutboardAccelAvg: 6 OA
 SG_ OAAvg_AccelX : 0|16@1- (0.001,0) [-32.768|32.767] "g" Vector_XXX
 SG_ OAAvg_AccelY : 16|16@1- (0.001,0) [-32.768|32.767] "g" Vector_XXX
 SG_ OAAvg_AccelZ : 32|16@1- (0.001,0) [-32.768|32.767] "g" Vector_XXX

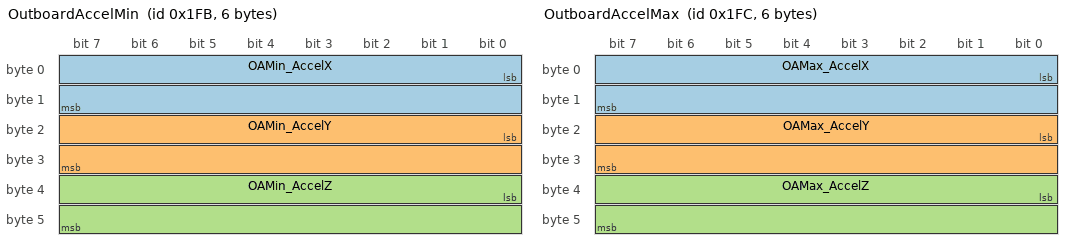
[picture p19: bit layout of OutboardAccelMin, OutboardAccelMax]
BO_ 507 OutboardAccelMin: 6 OA
 SG_ OAMin_AccelX : 0|16@1- (0.001,0) [-32.768|32.767] "g" Vector_XXX
 SG_ OAMin_AccelY : 16|16@1- (0.001,0) [-32.768|32.767] "g" Vector_XXX
 SG_ OAMin_AccelZ : 32|16@1- (0.001,0) [-32.768|32.767] "g" Vector_XXX

BO_ 508 OutboardAccelMax: 6 OA
 SG_ OAMax_AccelX : 0|16@1- (0.001,0) [-32.768|32.767] "g" Vector_XXX
 SG_ OAMax_AccelY : 16|16@1- (0.001,0) [-32.768|32.767] "g" Vector_XXX
 SG_ OAMax_AccelZ : 32|16@1- (0.001,0) [-32.768|32.767] "g" Vector_XXX

BO_ 530 VectorNav0: 8 VectorNav
 SG_ VectorNav_AccelX : 0|32@1+ (1,0) [0|0] "m/s^2" Vector__XXX
 SG_ VectorNav_AccelY : 32|32@1+ (1,0) [0|0] "m/s^2" Vector__XXX

BO_ 531 VectorNav1: 8 VectorNav
 SG_ VectorNav_AccelZ : 0|32@1+ (1,0) [0|0] "m/s^2" Vector__XXX
 SG_ VectorNav_AngularRateX : 32|32@1+ (1,0) [0|0] "rad/s" Vector__XXX

BO_ 532 VectorNav2: 8 VectorNav
 SG_ VectorNav_AngularRateY : 0|32@1+ (1,0) [0|0] "rad/s" Vector__XXX
 SG_ VectorNav_AngularRateZ : 32|32@1+ (1,0) [0|0] "rad/s" Vector__XXX

BO_ 533 VectorNav3: 8 VectorNav
 SG_ VectorNav_PosLlaL : 0|64@1+ (1,0) [0|0] "deg" Vector__XXX

BO_ 534 VectorNav4: 8 VectorNav
 SG_ VectorNav_PosLlaO : 0|64@1+ (1,0) [0|0] "deg" Vector__XXX

BO_ 535 VectorNav5: 8 VectorNav
 SG_ VectorNav_PosLlaA : 0|64@1+ (1,0) [0|0] "m" Vector__XXX

BO_ 536 VectorNav6: 8 VectorNav
 SG_ VectorNav_VelBodyX : 0|32@1+ (1,0) [0|0] "m/s" Vector__XXX
 SG_ VectorNav_VelBodyY : 32|32@1+ (1,0) [0|0] "m/s" Vector__XXX

BO_ 537 VectorNav7: 8 VectorNav
 SG_ VectorNav_VelBodyZ : 0|32@1+ (1,0) [0|0] "m/s" Vector__XXX
 SG_ VectorNav_YprY : 32|32@1+ (1,0) [0|0] "deg" Vector__XXX

BO_ 538 VectorNav8: 8 VectorNav
 SG_ VectorNav_YprP : 0|32@1+ (1,0) [0|0] "deg" Vector__XXX
 SG_ VectorNav_YprR : 32|32@1+ (1,0) [0|0] "deg" Vector__XXX

CM_ BU_ C70 "Bosch C70 Data Logger";
CM_ BU_ VC "Vehicle Controller";
CM_ BU_ BMS "Battery Management System";
CM_ BU_ CHG "Elcon HK-J Charger";
CM_ BU_ DASH "Dashboard Display";
CM_ BU_ SSDB "SSDB";
CM_ BU_ MCAN "MCAN";
CM_ BU_ OA "Outboard accelerometer";
CM_ BO_ 1790 "Wheel speeds, relayed by C70";
CM_ BO_ 1791 "Brake Pressures, relayed by C70";
BA_DEF_ SG_  "SystemSignalLongSymbol" STRING ;
BA_DEF_DEF_  "SystemSignalLongSymbol" "";
BA_ "SystemSignalLongSymbol" SG_ 469 D1_HV_Input_Current_Sensor_Valid "D1_HV_Input_Current_Sensor_Validity";
VAL_ 301 VC_Status_VehicleState 0 "VehicleState_NOT_READY" 1 "VehicleState_INVERTERS_POWERED" 2 "VehicleState_PRECHARGING" 3 "VehicleState_WAIT" 4 "VehicleState_STANDBY" 5 "VehicleState_RTD" 6 "VehicleState_SHUTDOWN";
VAL_ 301 VC_Status_ControlsLevel 0 "ControlsLevel_OFF" 1 "ControlsLevel_BASIC" 3 "ControlsLevel_ADVANCED" 2 "ControlsLevel_BASIC_VEL";
VAL_ 315 VC_HardFaultIndicator_task 0 "unknown" 1 "task_100Hz" ;
VAL_ 600 BMS_Status_ChargeState 0 "DISCONNECTED" 1 "CONNECTED" 2 "CONNECTED_CHARGING" 3 "CONNECTED_SETTLING" 4 "CONNECTED_BALANCING" 5 "CONNECTED_COMPLETE" 6 "CONNECTED_FAULTED";
VAL_ 701 BMS_FaultAlert_code 0 "FaultCode_SLAVE_COMM_CELLS" 1 "FaultCode_SLAVE_COMM_TEMPS" 2 "FaultCode_SLAVE_COMM_DRAIN_REQUEST" 3 "FaultCode_CURRENT_SENSOR_COMM" 4 "FaultCode_OVER_CURRENT" 5 "FaultCode_CELL_VOLTAGE_IRRATIONAL" 6 "FaultCode_CELL_VOLTAGE_DIFF" 7 "Faultcode_OUT_OF_JUICE" 8 "FaultCode_TEMPERATURE_IRRATIONAL" 9 "FaultCode_OVER_TEMP" 10 "FaultCode_DRAIN_FAILURE" ;
VAL_ 950 BMS_HardFaultIndicator_task 0 "unknown" 1 "task_1Hz" 2 "task_10Hz" 3 "task_1kHz" 4 "can_rx_task" ;
VAL_ 901 BMS_LimpMode_VoltageLimpLevel 0 "LimpModeLevel_NO_LIMP" 1 "LimpModeLevel_LEVEL_1" 2 "LimpModeLevel_LEVEL_2" 3 "LimpModeLevel_LEVEL_3" ;
VAL_ 901 BMS_LimpMode_TempLimpLevel 0 "LimpModeLevel_NO_LIMP" 1 "LimpModeLevel_LEVEL_1" 2 "LimpModeLevel_LEVEL_2" 3 "LimpModeLevel_LEVEL_3" ;

VAL_ 311 VC_RR_Status 5 "InvState_PAIRED_HARD" 4 "InvState_PAIRED_SOFT" 3 "InvState_LOST" 2 "InvState_HARD_FAULT" 1 "InvState_SOFT_FAULT" 0 "InvState_NORMAL" ;
VAL_ 311 VC_RL_Status 5 "InvState_PAIRED_HARD" 4 "InvState_PAIRED_SOFT" 3 "InvState_LOST" 2 "InvState_HARD_FAULT" 1 "InvState_SOFT_FAULT" 0 "InvState_NORMAL" ;
VAL_ 311 VC_FR_Status 5 "InvState_PAIRED_HARD" 4 "InvState_PAIRED_SOFT" 3 "InvState_LOST" 2 "InvState_HARD_FAULT" 1 "InvState_SOFT_FAULT" 0 "InvState_NORMAL" ;
VAL_ 311 VC_FL_Status 5 "InvState_PAIRED_HARD" 4 "InvState_PAIRED_SOFT" 3 "InvState_LOST" 2 "InvState_HARD_FAULT" 1 "InvState_SOFT_FAULT" 0 "InvState_NORMAL" ;

SIG_VALTYPE_ 505 VectorNav_VelBodyX : 1;
SIG_VALTYPE_ 505 VectorNav_VelBodyY : 1;

SIG_VALTYPE_ 530 VectorNav_AccelX : 1;
SIG_VALTYPE_ 530 VectorNav_AccelY : 1;
SIG_VALTYPE_ 531 VectorNav_AccelZ : 1;
SIG_VALTYPE_ 531 VectorNav_AngularRateX : 1;
SIG_VALTYPE_ 532 VectorNav_AngularRateY : 1;
SIG_VALTYPE_ 532 VectorNav_AngularRateZ : 1;
SIG_VALTYPE_ 533 VectorNav_PosLlaL : 2;
SIG_VALTYPE_ 534 VectorNav_PosLlaO : 2;
SIG_VALTYPE_ 535 VectorNav_PosLlaA : 2;
SIG_VALTYPE_ 536 VectorNav_VelBodyX : 1;
SIG_VALTYPE_ 536 VectorNav_VelBodyY : 1;
SIG_VALTYPE_ 537 VectorNav_VelBodyZ : 1;
SIG_VALTYPE_ 537 VectorNav_YprY : 1;
SIG_VALTYPE_ 538 VectorNav_YprP : 1;
SIG_VALTYPE_ 538 VectorNav_YprR : 1;

SIG_VALTYPE_ 328 VC_debug1 : 1;
SIG_VALTYPE_ 328 VC_debug2 : 1;
SIG_VALTYPE_ 329 VC_YawRateProportional : 1;
SIG_VALTYPE_ 329 VC_YawRateIntegral : 1;
SIG_VALTYPE_ 330 VC_YawRateFeedForward : 1;
SIG_VALTYPE_ 331 VC_CodegenRR : 1;
SIG_VALTYPE_ 331 VC_CodegenRL : 1;
SIG_VALTYPE_ 332 VC_CodegenFR : 1;
SIG_VALTYPE_ 332 VC_CodegenFL : 1;
